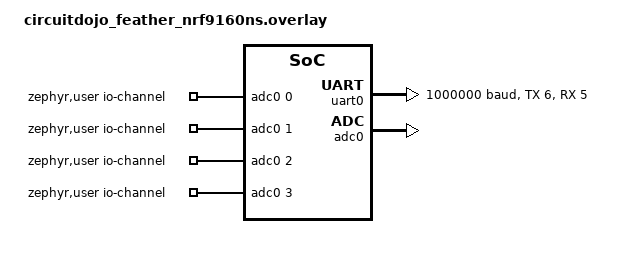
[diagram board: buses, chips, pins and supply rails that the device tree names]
/ {
    aliases {
        bootloader-led0 = &blue_led;
    };
};

// Configuration for UART0
&uart0 {
    status = "okay";
    current-speed = <1000000>; // Baud rate set to 115200 bps
    tx-pin = <6>;            // Transmit pin set to GPIO pin 6
    rx-pin = <5>;            // Receive pin set to GPIO pin 5
};


/ {
	zephyr,user {
		io-channels =
			<&adc0 0>,
			<&adc0 1>,
			<&adc0 2>,
			<&adc0 3>;
	};
};

&adc0 {
status = "okay";
};
